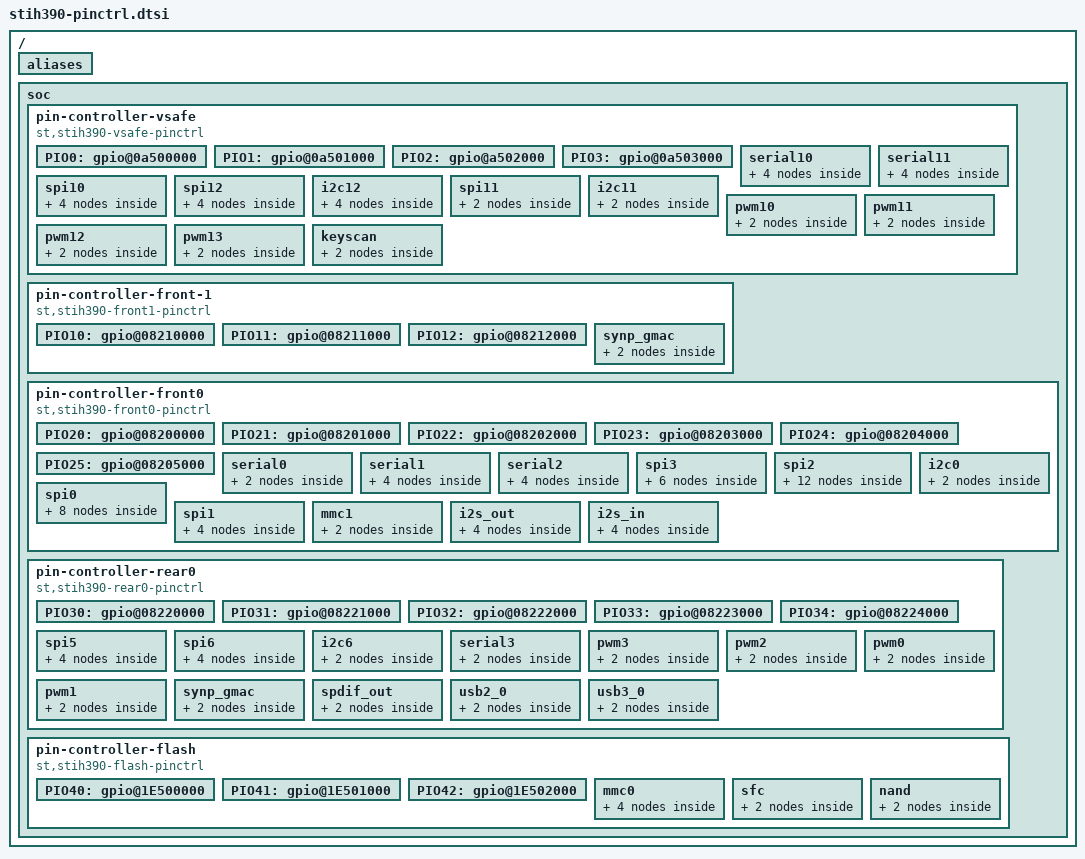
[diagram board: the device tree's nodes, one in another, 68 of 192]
/*
 * Copyright (C) 2015 STMicroelectronics Limited.
 * Author: Guillaume Kouadio Carry <guillaume.kouadio-carry@st.com>
 *
 * This program is free software; you can redistribute it and/or modify
 * it under the terms of the GNU General Public License version 2 as
 * published by the Free Software Foundation.
 */

#include <dt-bindings/pinctrl/st-pincfg.h>
#include <dt-bindings/interrupt-controller/arm-gic.h>
/ {
	aliases {
		/* PIO for FC_BACKBONE */

		/* 0-3: PIO_VSAFE */
		gpio0 = &PIO0;
		gpio1 = &PIO1;
		gpio2 = &PIO2;
		gpio3 = &PIO3;

		/* 10-12: PIO_FRONT1 */
		gpio4 = &PIO10;
		gpio5 = &PIO11;
		gpio6 = &PIO12;

		/* 20-25: PIO_FRONT0 */
		gpio7 = &PIO20;
		gpio8 = &PIO21;
		gpio9 = &PIO22;
		gpio10 = &PIO23;
		gpio11 = &PIO24;
		gpio12 = &PIO25;

		/* 30-34: PIO_REAR */
		gpio13 = &PIO30;
		gpio14 = &PIO31;
		gpio15 = &PIO32;
		gpio16 = &PIO33;
		gpio17 = &PIO34;

		/* 40-42: PIO_FLASH */
		gpio18 = &PIO40;
		gpio19 = &PIO41;
		gpio20 = &PIO42;

	};

	soc {
		/* FC_VSAFE PIO_VSAFE */
		pin-controller-vsafe{
			#address-cells = <1>;
			#size-cells = <1>;
			compatible = "st,stih390-vsafe-pinctrl";
			st,syscfg = <&syscfg_pio_vsafe>;
			ranges = <0 0x0a500000 0x4000>;
			reg = <0x0a50f080 0x4>;
			reg-names = "irqmux";
			interrupts = <GIC_SPI 198 IRQ_TYPE_NONE>;
			interrupts-names = "irqmux";

			PIO0: gpio@0a500000 {
				gpio-controller;
				#gpio-cells = <2>;
				reg = <0x0 0x100>;
				st,bank-name = "PIO0";
				interrupt-controller;
				#interrupt-cells = <2>;
			};

			PIO1: gpio@0a501000 {
				gpio-controller;
				#gpio-cells = <2>;
				reg = <0x1000 0x100>;
				st,bank-name = "PIO1";
				interrupt-controller;
				#interrupt-cells = <2>;
			};

			PIO2: gpio@a502000 {
				gpio-controller;
				#gpio-cells = <2>;
				reg = <0x2000 0x100>;
				st,bank-name = "PIO2";
				interrupt-controller;
				#interrupt-cells = <2>;
			};

			PIO3: gpio@0a503000 {
				gpio-controller;
				#gpio-cells = <2>;
				reg = <0x3000 0x100>;
				st,bank-name = "PIO3";
				interrupt-controller;
				#interrupt-cells = <2>;
			};

			serial10 {
				 pinctrl_vsafe_serial10_alt1_0: serial10_alt1-0 {
					st,pins {
						tx = <&PIO0 1 ALT1 OUT>;
						rx = <&PIO0 2 ALT1 IN>;
					};
				 };
				 pinctrl_vsafe_serial10_alt2_0: serial10_alt2-0 {
					st,pins {
						tx = <&PIO1 1 ALT2 OUT>;
						rx = <&PIO1 0 ALT2 IN>;
					};
				};
			};

			serial11 {
				 pinctrl_vsafe_serial11_alt2_0: serial11_alt2-0 {
					st,pins {
						tx = <&PIO0 4 ALT2 OUT>;
						rx = <&PIO0 7 ALT2 IN>;
					};
				};
				 pinctrl_vsafe_serial11_alt2_1: serial11_alt2-1 {
					st,pins {
						tx = <&PIO1 4 ALT2 OUT>;
						rx = <&PIO1 5 ALT2 IN>;
					};
				};
			};

			spi10 {
			       pinctrl_vsafe_spi10_4w_alt1_0: spi10_4w_alt1-0 {
					st,pins {
						 mrst = <&PIO0 7 ALT1 BIDIR>;
						 scl = <&PIO0 5 ALT1 BIDIR>;
						 mtsr = <&PIO0 6 ALT1 BIDIR>;
					};
			       };
			       pinctrl_vsafe_spi10_4w_alt2_0: spi10_4w_alt2-0 {
					st,pins {
						 mrst = <&PIO0 3 ALT2 BIDIR>;
						 scl = <&PIO0 1 ALT2 BIDIR>;
						 mtsr = <&PIO0 2 ALT2 BIDIR>;
					};
			       };
			};

			spi12 {
			       pinctrl_vsafe_spi12_4w_alt1_0: spi12_4w_alt1-0 {
					st,pins {
						 mrst = <&PIO1 0 ALT1 BIDIR>;
						 scl = <&PIO1 3 ALT1 BIDIR>;
						 mtsr = <&PIO1 2 ALT1 BIDIR>;
					};
			       };
			       pinctrl_vsafe_spi12_4w_alt2_0: spi12_4w_alt2-0 {
					st,pins {
						 mrst = <&PIO2 3 ALT2 BIDIR>;
						 scl = <&PIO2 1 ALT2 BIDIR>;
						 mtsr = <&PIO2 2 ALT2 BIDIR>;
					};
			       };
			};

			i2c12 {
			       pinctrl_vsafe_i2c12_alt1_0: i2c12_alt1-0 {
					st,pins {
						 scl = <&PIO1 3 ALT1 BIDIR>;
						 sda = <&PIO1 2 ALT1 BIDIR>;
					};
			       };
			       pinctrl_vsafe_i2c12_alt2_0: i2c12_alt2-0 {
					st,pins {
						 scl = <&PIO2 1 ALT2 BIDIR>;
						 sda = <&PIO2 2 ALT2 BIDIR>;
					};
			       };
			};

			spi11 {
			       pinctrl_vsafe_spi11_3w_alt1_0: spi13_3w_alt1-0 {
					st,pins {
						 scl = <&PIO2 4 ALT1 BIDIR>;
						 mtsr = <&PIO2 5 ALT1 BIDIR>;
					};
			       };
			};

			i2c11 {
			       pinctrl_vsafe_i2c11_alt1_0: i2c11_alt1-0 {
					st,pins {
						 scl = <&PIO2 4 ALT1 BIDIR>;
						 sda = <&PIO2 5 ALT1 BIDIR>;
					};
			       };
			};

			pwm10 {
				pinctrl_vsafe_pwm10: pwm10-0 {
					st,pins {
						pwm_out = <&PIO0 4 ALT1 OUT>;
					};
				};
			};

			pwm11 {
				pinctrl_vsafe_pwm11: pwm11-0 {
					st,pins {
						pwm_out = <&PIO0 7 ALT3 OUT>;
					};
				};
			};

			pwm12 {
				pinctrl_vsafe_pwm12: pwm12-0 {
					st,pins {
						pwm_out = <&PIO2 2 ALT3 OUT>;
					};
				};
			};

			pwm13 {
				pinctrl_vsafe_pwm13: pwm13-0 {
					st,pins {
						pwm_out = <&PIO2 3 ALT3 OUT>;
					};
				};
			};

			keyscan {
				pinctrl_keyscan: keyscan {
					st,pins {
						keyin0 = <&PIO1 4 ALT1 IN>;
						keyin1 = <&PIO1 5 ALT1 IN>;
						keyin2 = <&PIO2 0 ALT1 IN>;
						keyin3 = <&PIO2 1 ALT2 IN>;
						keyout0 = <&PIO1 6 ALT1 OUT>;
						keyout1 = <&PIO1 7 ALT1 OUT>;
						keyout2 = <&PIO2 2 ALT1 OUT>;
						keyout3 = <&PIO2 3 ALT1 OUT>;
					};
				};
			};
		};

		/* FC_BACKBONE PIO_FRONT1 */
		pin-controller-front-1 {
			#address-cells = <1>;
			#size-cells = <1>;
			compatible = "st,stih390-front1-pinctrl";
			st,syscfg = <&syscfg_pio_front_1>;
			ranges = <0 0x08210000 0x6000>;
			reg = <0x0821f080 0x4>;
			reg-names = "irqmux";
			interrupts = <GIC_SPI 200 IRQ_TYPE_NONE>;
			interrupts-names = "irqmux";

			PIO10: gpio@08210000 {
				gpio-controller;
				#gpio-cells = <2>;
				reg = <0x0 0x100>;
				st,bank-name = "PIO10";
				interrupt-controller;
				#interrupt-cells = <2>;
			};

			PIO11: gpio@08211000 {
				gpio-controller;
				#gpio-cells = <2>;
				reg = <0x1000 0x100>;
				st,bank-name = "PIO11";
				interrupt-controller;
				#interrupt-cells = <2>;
			};

			PIO12: gpio@08212000 {
				gpio-controller;
				#gpio-cells = <2>;
				reg = <0x2000 0x100>;
				st,bank-name = "PIO12";
				interrupt-controller;
				#interrupt-cells = <2>;
			};

			synp_gmac {
				pinctrl_front1_rgmii: rgmii {
					st,pins {
						txd0 = <&PIO10 0 ALT2 OUT DE_IO 0 CLK_A>;
						txd1 = <&PIO10 1 ALT2 OUT DE_IO 0 CLK_A>;
						txd2 = <&PIO10 2 ALT2 OUT DE_IO 0 CLK_A>;
						txd3 = <&PIO10 3 ALT2 OUT DE_IO 0 CLK_A>;
						txen = <&PIO11 6 ALT2 OUT DE_IO 0 CLK_A>;
						txclk = <&PIO11 7 ALT2 OUT NICLK 0 CLK_A>;

						mdio = <&PIO11 0 ALT2 BIDIR_PU BYPASS 0>;
						mdc = <&PIO11 2 ALT2 OUT NICLK 0 CLK_A>;
						mdint = <&PIO11 3 ALT2 IN BYPASS 0>;
						rxd0 = <&PIO10 4 ALT2 IN DE_IO 0 CLK_A>;
						rxd1 = <&PIO10 5 ALT2 IN DE_IO 0 CLK_A>;
						rxd2 = <&PIO10 6 ALT2 IN DE_IO 0 CLK_A>;
						rxd3 = <&PIO10 7 ALT2 IN DE_IO 0 CLK_A>;

						rxdv = <&PIO11 1 ALT2 IN DE_IO 0 CLK_A>;
						rxclk = <&PIO11 5 ALT2 IN NICLK 0 CLK_A>;
						phyclk = <&PIO11 4 ALT2 OUT NICLK 1750 CLK_A>;
					};
				};
			};
		};

		/* FC_BACKBONE PIO_FRONT0 */
		pin-controller-front0 {
			#address-cells = <1>;
			#size-cells = <1>;
			compatible = "st,stih390-front0-pinctrl";
			st,syscfg = <&syscfg_pio_front_0>;
			ranges = <0 0x08200000 0x6000>;
			reg = <0x0820f080 0x4>;
			reg-names = "irqmux";
			interrupts = <GIC_SPI 199 IRQ_TYPE_NONE>;
			interrupts-names = "irqmux";

			PIO20: gpio@08200000 {
				gpio-controller;
				#gpio-cells = <2>;
				reg = <0x0 0x100>;
				st,bank-name = "PIO20";
				interrupt-controller;
				#interrupt-cells = <2>;
			};

			PIO21: gpio@08201000 {
				gpio-controller;
				#gpio-cells = <2>;
				reg = <0x1000 0x100>;
				st,bank-name = "PIO21";
				interrupt-controller;
				#interrupt-cells = <2>;
			};

			PIO22: gpio@08202000 {
				gpio-controller;
				#gpio-cells = <2>;
				reg = <0x2000 0x100>;
				st,bank-name = "PIO22";
				interrupt-controller;
				#interrupt-cells = <2>;
			};

			PIO23: gpio@08203000 {
				gpio-controller;
				#gpio-cells = <2>;
				reg = <0x3000 0x100>;
				st,bank-name = "PIO23";
				interrupt-controller;
				#interrupt-cells = <2>;
			};

			PIO24: gpio@08204000 {
				gpio-controller;
				#gpio-cells = <2>;
				reg = <0x4000 0x100>;
				st,bank-name = "PIO24";
				interrupt-controller;
				#interrupt-cells = <2>;
			};

			PIO25: gpio@08205000 {
				gpio-controller;
				#gpio-cells = <2>;
				reg = <0x5000 0x100>;
				st,bank-name = "PIO25";
				interrupt-controller;
				#interrupt-cells = <2>;
			};

			serial0 {
				pinctrl_front0_serial0: serial0-0 {
					st,pins {
						tx = <&PIO21 0 ALT2 OUT>;
						rx = <&PIO21 1 ALT2 IN>;
					};
				};
			};

			serial1 {
				pinctrl_front0_serial1_alt2_0: serial1_alt2-0 {
					st,pins {
						tx = <&PIO22 7 ALT2 OUT>;
						rx = <&PIO23 0 ALT2 IN>;
					};
				};
				pinctrl_front0_serial1_alt3_0: serial1_alt3-0 {
					st,pins {
						tx = <&PIO25 2 ALT3 OUT>;
						rx = <&PIO25 2 ALT3 IN>;
					};
				};
			};

			serial2 {
				pinctrl_front0_serial2_alt2_0: serial2-alt2-0 {
					st,pins {
						tx = <&PIO23 3 ALT2 OUT>;
						rx = <&PIO23 4 ALT2 IN>;
					};
				};
				pinctrl_front0_serial2_alt2_1: serial2_alt2-1 {
					st,pins {
						tx = <&PIO24 4 ALT2 OUT>;
						rx = <&PIO24 7 ALT2 IN>;
					};
				};
			};

			spi3 {
			      pinctrl_front0_spi3_4w_alt2_0: spi3_4w_alt2-0 {
					st,pins {
						 mrst = <&PIO21 5 ALT2 BIDIR>;
						 scl = <&PIO21 6 ALT2 BIDIR>;
						 mtsr = <&PIO21 7 ALT2 BIDIR>;
					};
			      };
			      pinctrl_front0_spi3_3w_alt2_0: spi3_3w_alt2-0 {
					st,pins {
						 scl = <&PIO21 6 ALT2 BIDIR>;
						 mtsr = <&PIO21 7 ALT2 BIDIR>;
					};
			      };
			      pinctrl_front0_spi3_4w_alt3_0: spi3_4w_alt3-0 {
					st,pins {
						 scl = <&PIO24 5 ALT3 BIDIR>;
						 mtsr = <&PIO24 6 ALT3 BIDIR>;
						 mrst = <&PIO24 4 ALT3 BIDIR>;
					};
			      };
			};

			spi2 {
			      pinctrl_front0_spi2_4w_alt2_0: spi2_4w_alt2-0 {
					st,pins {
						 mrst = <&PIO24 2 ALT2 BIDIR>;
						 scl = <&PIO24 0 ALT2 BIDIR>;
						 mtsr = <&PIO24 1 ALT2 BIDIR>;
					};
			      };
			      pinctrl_front0_spi2_3w_alt2_0: spi2_3w_alt2-0 {
					st,pins {
						 scl = <&PIO24 0 ALT2 BIDIR>;
						 mtsr = <&PIO24 1 ALT2 BIDIR>;
					};
			      };

			      pinctrl_front0_spi2_4w_alt2_1: spi2_4w_alt2-1 {
					st,pins {
						 mrst = <&PIO25 5 ALT2 BIDIR>;
						 scl = <&PIO25 6 ALT2 BIDIR>;
						 mtsr = <&PIO25 7 ALT2 BIDIR>;
					};
			      };
			      pinctrl_front0_spi2_3w_alt2_1: spi2_3w_alt2-1 {
					st,pins {
						 scl = <&PIO25 6 ALT2 BIDIR>;
						 mtsr = <&PIO25 7 ALT2 BIDIR>;
					};
			      };
			      pinctrl_front0_spi2_4w_alt4_0: spi2_4w_alt4-0 {
					st,pins {
						 scl = <&PIO23 6 ALT4 BIDIR>;
						 mtsr = <&PIO23 5 ALT4 BIDIR>;
						 mrst = <&PIO23 7 ALT4 BIDIR>;
					};
			      };
			      pinctrl_front0_spi2_3w_alt4_0: spi2_3w_alt4-0 {
					st,pins {
						 scl = <&PIO23 6 ALT4 BIDIR>;
						 mtsr = <&PIO23 5 ALT4 BIDIR>;
					};
			      };

			};

			i2c0 {
			      pinctrl_front0_i2c0_alt3_0: i2c0_alt3-0 {
					st,pins {
						 scl = <&PIO21 2 ALT3 BIDIR>;
						 sda = <&PIO21 3 ALT3 BIDIR>;
					};
			      };
			};

			spi0 {
			      pinctrl_front0_spi0_4w_alt3_0: spi0_4w_alt3-0 {
					st,pins {
						 scl = <&PIO22 4 ALT3 BIDIR>;
						 mtsr = <&PIO22 5 ALT3 BIDIR>;
						 mrst = <&PIO22 6 ALT3 BIDIR>;
					};
			      };
			      pinctrl_front0_spi0_3w_alt3_0: spi0_3w_alt3-0 {
					st,pins {
						 scl = <&PIO22 4 ALT3 BIDIR>;
						 mtsr = <&PIO22 5 ALT3 BIDIR>;
					};
			      };
			      pinctrl_front0_spi0_4w_alt2_0: spi0_4w_alt2-0 {
					st,pins {
						 scl = <&PIO25 2 ALT2 BIDIR>;
						 mtsr = <&PIO25 3 ALT2 BIDIR>;
						 mrst = <&PIO25 4 ALT2 BIDIR>;
					};
			      };
			      pinctrl_front0_spi0_3w_alt2_0: spi0_3w_alt2-0 {
					st,pins {
						 scl = <&PIO25 2 ALT2 BIDIR>;
						 mtsr = <&PIO25 3 ALT2 BIDIR>;
					};
			      };
			};

			spi1 {
			      pinctrl_front0_spi1_4w_alt3_0: spi1_4w_alt3-0 {
					st,pins {
						 scl = <&PIO22 7 ALT3 BIDIR>;
						 mtsr = <&PIO23 0 ALT3 BIDIR>;
						 mrst = <&PIO23 1 ALT3 BIDIR>;
					};
			      };
			      pinctrl_front0_spi1_3w_alt3_0: spi1_3w_alt3-0 {
					st,pins {
						 scl = <&PIO22 7 ALT3 BIDIR>;
						 mtsr = <&PIO23 0 ALT3 BIDIR>;
					};
			      };
			};

			mmc1 {
				pinctrl_sd1: sd1-0 {
					st,pins {
						sd_clk = <&PIO24 0 ALT5 BIDIR>;
						sd_cmd = <&PIO24 1 ALT5 BIDIR>;
						sd_dat0 = <&PIO24 2 ALT5 BIDIR>;
						sd_dat1 = <&PIO24 3 ALT5 BIDIR>;
						sd_dat2 = <&PIO24 4 ALT5 BIDIR>;
						sd_dat3 = <&PIO25 2 ALT5 BIDIR>;
						sd_led = <&PIO25 6 ALT5 OUT>;
						sd_pwren = <&PIO25 5 ALT5 OUT>;
						sd_cd = <&PIO25 3 ALT5 IN>;
						sd_wp = <&PIO25 4 ALT5 IN>;
					};
				};
			};

			i2s_out {
				pinctrl_i2s_8ch_out: i2s_8ch_out{
					st,pins {
						mclk = <&PIO22 4 ALT6 OUT>;
						lrclk = <&PIO22 6 ALT6 OUT>;
						sclk = <&PIO22 5 ALT6 OUT>;
						data0 = <&PIO23 0 ALT6 OUT>;
						data1 = <&PIO23 1 ALT6 OUT>;
						data2 = <&PIO23 2 ALT6 OUT>;
						data3 = <&PIO22 7 ALT6 OUT>;
					};
				};

				pinctrl_i2s_2ch_out: i2s_2ch_out{
					st,pins {
						mclk = <&PIO22 4 ALT6 OUT>;
						lrclk = <&PIO22 6 ALT6 OUT>;
						sclk = <&PIO22 5 ALT6 OUT>;
						data0 = <&PIO23 0 ALT6 OUT>;
					};
				};
			};

			i2s_in {
				pinctrl_i2s_8ch_in: i2s_8ch_in{
					st,pins {
						mclk = <&PIO23 0 ALT5 IN>;
						lrclk = <&PIO23 2 ALT5 IN>;
						sclk = <&PIO23 1 ALT5 IN>;
						data0 = <&PIO22 7 ALT5 IN>;
						data1 = <&PIO22 6 ALT5 IN>;
						data2 = <&PIO22 5 ALT5 IN>;
						data3 = <&PIO22 4 ALT5 IN>;
					};
				};

				pinctrl_i2s_2ch_in: i2s_2ch_in{
					st,pins {
						lrclk = <&PIO23 2 ALT5 IN>;
						sclk = <&PIO23 1 ALT5 IN>;
						data0 = <&PIO22 7 ALT5 IN>;
					};
				};
			};

	 	};

		/* FC_BACKBONE PIO_REAR */
		pin-controller-rear0 {
			#address-cells = <1>;
			#size-cells = <1>;
			compatible = "st,stih390-rear0-pinctrl";
			st,syscfg = <&syscfg_pio_rear_0>;
			ranges = <0 0x08220000 0x6000>;
			reg = <0x0822f080 0x4>;
			reg-names = "irqmux";
			interrupts = <GIC_SPI 201 IRQ_TYPE_NONE>;
			interrupts-names = "irqmux";

			PIO30: gpio@08220000 {
				gpio-controller;
				#gpio-cells = <2>;
				reg = <0x0 0x100>;
				st,bank-name = "PIO30";
				interrupt-controller;
				#interrupt-cells = <2>;
			};

			PIO31: gpio@08221000 {
				gpio-controller;
				#gpio-cells = <2>;
				reg = <0x1000 0x100>;
				st,bank-name = "PIO31";
				interrupt-controller;
				#interrupt-cells = <2>;
			};

			PIO32: gpio@08222000 {
				gpio-controller;
				#gpio-cells = <2>;
				reg = <0x2000 0x100>;
				st,bank-name = "PIO32";
				interrupt-controller;
				#interrupt-cells = <2>;
			};

			PIO33: gpio@08223000 {
				gpio-controller;
				#gpio-cells = <2>;
				reg = <0x3000 0x100>;
				st,bank-name = "PIO33";
				interrupt-controller;
				#interrupt-cells = <2>;
			};

			PIO34: gpio@08224000 {
				gpio-controller;
				#gpio-cells = <2>;
				reg = <0x4000 0x100>;
				st,bank-name = "PIO34";
				interrupt-controller;
				#interrupt-cells = <2>;
			};

			spi5 {
			      pinctrl_rear0_spi5_4w_alt1_0: spi5_4w_alt1-0 {
					st,pins {
						 scl = <&PIO32 0 ALT1 BIDIR>;
						 mtsr = <&PIO32 1 ALT1 BIDIR>;
						 mrst = <&PIO32 2 ALT1 BIDIR>;
					};
			      };
			      pinctrl_rear0_spi5_3w_alt1_0: spi5_3w_alt1-0 {
					st,pins {
						 scl = <&PIO32 0 ALT1 BIDIR>;
						 mtsr = <&PIO32 1 ALT1 BIDIR>;
					};
			      };
			};

			spi6 {
			      pinctrl_rear0_spi6_4w_alt1_0: spi6_4w_alt1-0 {
					st,pins {
						 scl = <&PIO32 3 ALT1 BIDIR>;
						 mtsr = <&PIO32 4 ALT1 BIDIR>;
						 mrst = <&PIO33 1 ALT1 BIDIR>;
					};
			      };
			      pinctrl_rear0_spi6_3w_alt1_0: spi6_3w_alt1-0 {
					st,pins {
						 scl = <&PIO32 3 ALT1 BIDIR>;
						 mtsr = <&PIO32 4 ALT1 BIDIR>;
					};
			      };

			};

			i2c6 {
			      pinctrl_rear0_i2c6_alt1_0: i2c6_alt1-0 {
					st,pins {
						 scl = <&PIO32 3 ALT1 BIDIR>;
						 sda = <&PIO32 4 ALT1 BIDIR>;
					};
			      };
			};

			serial3 {
				pinctrl_rear0_serial3_alt1_0: serial3_alt1-0 {
					st,pins {
						tx = <&PIO32 6 ALT1 OUT>;
						rx = <&PIO32 5 ALT1 IN>;
					};
				};
			};

			pwm3 {
				pinctrl_rear0_pwm3: pwm3-0 {
					st,pins {
						pwm_out = <&PIO30 3 ALT2 OUT>;
					};
				};
			};
			pwm2 {
				pinctrl_rear0_pwm2: pwm2-0 {
					st,pins {
						pwm_out = <&PIO32 7 ALT2 OUT>;
					};
				};
			};
			pwm0 {
				pinctrl_rear0_pwm0: pwm0-0 {
					st,pins {
						pwm_out = <&PIO33 0 ALT2 OUT>;
					};
				};
			};
			pwm1 {
				pinctrl_rear0_pwm1: pwm1-0 {
					st,pins {
						pwm_out = <&PIO33 7 ALT1 OUT>;
					};
				};
			};

			synp_gmac {
				pinctrl_rear0_rgmii4: rgmii-4 {
					st,pins {
						txd0 = <&PIO30 0 ALT1 OUT DE_IO 0 CLK_A>;
						txd1 = <&PIO30 1 ALT1 OUT DE_IO 0 CLK_A>;
						txd2 = <&PIO30 2 ALT1 OUT DE_IO 0 CLK_A>;
						txd3 = <&PIO30 3 ALT1 OUT DE_IO 0 CLK_A>;
						txen = <&PIO31 6 ALT1 OUT DE_IO 0 CLK_A>;
						txclk = <&PIO31 7 ALT1 OUT NICLK 0 CLK_A>;

						mdio = <&PIO31 0 ALT1 BIDIR_PU BYPASS 0>;
						mdc = <&PIO31 2 ALT1 OUT NICLK 0 CLK_A>;
						mdint = <&PIO31 1 ALT1 IN BYPASS 0>;
						rxd0 = <&PIO30 4 ALT1 IN DE_IO 0 CLK_A>;
						rxd1 = <&PIO30 5 ALT1 IN DE_IO 0 CLK_A>;
						rxd2 = <&PIO30 6 ALT1 IN DE_IO 0 CLK_A>;
						rxd3 = <&PIO30 7 ALT1 IN DE_IO 0 CLK_A>;

						rxdv = <&PIO31 3 ALT1 IN DE_IO 0 CLK_A>;
						rxclk = <&PIO31 5 ALT1 IN NICLK 0 CLK_A>;
						phyclk = <&PIO31 4 ALT1 OUT NICLK 1750 CLK_A>;
					};
				};
			};

			spdif_out {
				pinctrl_spdif_out: spdif_out{
					st,pins {
						spdif_out = <&PIO33 2 ALT1 OUT>;
					};
				};
			};

			usb2_0 {
				pinctrl_rear0_usb2_0: usb2_0-0 {
					st,pins {
						oc-detect = <&PIO33 4 ALT1 IN>;
						pwr-enable = <&PIO33 5 ALT1 OUT>;
					};
				};
			};

			usb3_0 {
				pinctrl_rear0_usb3_0: usb3_0-0 {
					st,pins {
						oc-detect = <&PIO33 3 ALT1 IN>;
						pwr-enable = <&PIO33 6 ALT1 OUT>;
					};
				};
			};
		};
		pin-controller-flash {
			#address-cells = <1>;
			#size-cells = <1>;
			compatible = "st,stih390-flash-pinctrl";
			st,syscfg = <&syscfg_pio_flash>;
			ranges = <0 0x1E500000 0x3000>;
			reg = <0x1E50f080 0x4>;
			reg-names = "irqmux";
			interrupts = <GIC_SPI 202 IRQ_TYPE_NONE>;
			interrupt-names = "irqmux";

			PIO40: gpio@1E500000 {
				gpio-controller;
				#gpio-cells = <2>;
				interrupt-controller;
				#interrupt-cells = <2>;
				reg = <0 0x100>;
				st,bank-name = "PIO40";
			};
			PIO41: gpio@1E501000 {
				gpio-controller;
				#gpio-cells = <2>;
				interrupt-controller;
				#interrupt-cells = <2>;
				reg = <0x1000 0x100>;
				st,bank-name = "PIO41";
			};
			PIO42: gpio@1E502000 {
				gpio-controller;
				#gpio-cells = <2>;
				interrupt-controller;
				#interrupt-cells = <2>;
				reg = <0x2000 0x100>;
				st,bank-name = "PIO42";
			};

			mmc0 {
				pinctrl_emmc0: emmc0-0 {
					st,pins {
						emmc_clk = <&PIO40 6 ALT1 BIDIR>;
						emmc_cmd = <&PIO40 7 ALT1 BIDIR>;
						emmc_d0 = <&PIO41 0 ALT1 BIDIR>;
						emmc_d1 = <&PIO41 1 ALT1 BIDIR>;
						emmc_d2 = <&PIO41 2 ALT1 BIDIR>;
						emmc_d3 = <&PIO41 3 ALT1 BIDIR>;
						emmc_d4 = <&PIO41 4 ALT1 BIDIR>;
						emmc_d5 = <&PIO41 5 ALT1 BIDIR>;
						emmc_d6 = <&PIO41 6 ALT1 BIDIR>;
						emmc_d7 = <&PIO41 7 ALT1 BIDIR>;
					};
				};
				pinctrl_sd0: sd0-0 {
					st,pins {
						SD_CLK = <&PIO40 6 ALT2 BIDIR>;
						SD_CMD = <&PIO40 7 ALT2 BIDIR>;
						SD_DAT0 = <&PIO41 0 ALT2 BIDIR>;
						SD_DAT1 = <&PIO41 1 ALT2 BIDIR>;
						SD_DAT2 = <&PIO41 2 ALT2 BIDIR>;
						SD_DAT3 = <&PIO41 3 ALT2 BIDIR>;
						SD_LED = <&PIO42 0 ALT2 OUT>;
						SD_PWREN = <&PIO42 2 ALT2 OUT>;
						SD_VSEL = <&PIO42 3 ALT2 OUT>;
						SD_CD = <&PIO42 4 ALT2 IN>;
						SD_WP = <&PIO42 5 ALT2 IN>;
					};
				};
			};

			sfc {
				pinctrl_sfc: sfc {
					st,pins {
						spi-sfc-clk = <&PIO40 1 ALT1 OUT>;
						spi-sfc-cs = <&PIO40 0 ALT1 OUT>;
						spi-sfc-mosi = <&PIO40 2 ALT1 OUT>;
						spi-sfc-miso = <&PIO40 3 ALT1 IN>;
						spi-sfc-hol = <&PIO40 5 ALT1 OUT>;
						spi-sfc-wp = <&PIO40 4 ALT1 OUT>;
					};
				};
			};

			nand {
				pinctrl_nand: nand {
					st,pins {
						nand_cs2 = <&PIO40 4 ALT3 OUT>;
						nand_cs3 = <&PIO40 5 ALT3 OUT>;
						nand_cs1 = <&PIO40 6 ALT3 OUT>;
						nand_cs0 = <&PIO40 7 ALT3 OUT>;
						nand_d0 = <&PIO41 0 ALT3 BIDIR>;
						nand_d1 = <&PIO41 1 ALT3 BIDIR>;
						nand_d2 = <&PIO41 2 ALT3 BIDIR>;
						nand_d3 = <&PIO41 3 ALT3 BIDIR>;
						nand_d4 = <&PIO41 4 ALT3 BIDIR>;
						nand_d5 = <&PIO41 5 ALT3 BIDIR>;
						nand_d6 = <&PIO41 6 ALT3 BIDIR>;
						nand_d7 = <&PIO41 7 ALT3 BIDIR>;
						nand_we = <&PIO42 0 ALT3 OUT>;
						nand_ale = <&PIO42 2 ALT3 OUT>;
						nand_cle = <&PIO42 3 ALT3 OUT>;
						nand_rnb = <&PIO42 4 ALT3 IN>;
						nand_ren = <&PIO42 5 ALT3 OUT>;
					};
				};
			};
		};
	};
};

